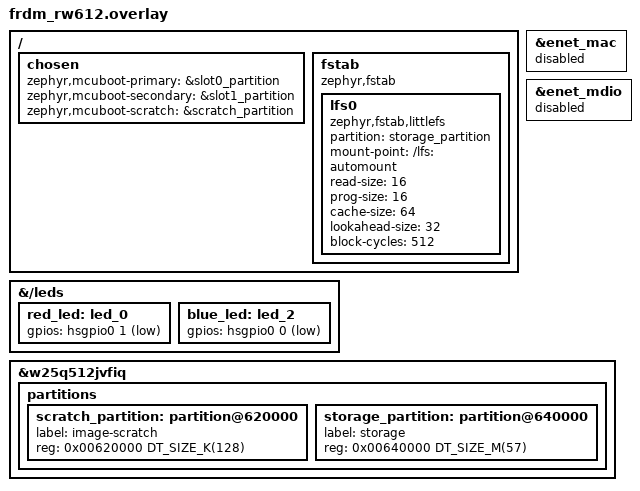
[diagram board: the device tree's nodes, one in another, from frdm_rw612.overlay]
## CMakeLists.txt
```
include(cmake/warn_all.cmake)

cmake_minimum_required(VERSION 3.20.0)

# Auto-include credentials.conf if present — keep it out of git
if(EXISTS ${CMAKE_CURRENT_SOURCE_DIR}/credentials.conf)
  list(APPEND EXTRA_CONF_FILE ${CMAKE_CURRENT_SOURCE_DIR}/credentials.conf)
endif()

find_package(Zephyr REQUIRED HINTS $ENV{ZEPHYR_BASE})
project(firmups_device LANGUAGES C)

warn_all(app)
target_include_directories(app PRIVATE include)
target_sources(app PRIVATE src/main.c src/application/common/fatal_error.c src/driver/common/filesystem.c)

if(${BOARD} MATCHES "native")
  zephyr_compile_options(-fsanitize-undefined-trap-on-error)
  target_sources(app PRIVATE
    src/udpclient.c
    src/application/native/firmware_updater.c
    src/driver/native/led.c
    src/driver/native/button.c)
  target_compile_definitions(app PUBLIC NATIVE_SIM)
elseif(${BOARD} MATCHES "nrf5340dk")
  target_sources(app PRIVATE
    src/application/nrf5340dk/firmware_updater.c
    src/driver/nrf5340dk/led.c
    src/driver/nrf5340dk/button.c)
  target_compile_definitions(app PUBLIC NRF5340DK)
elseif(${BOARD} MATCHES "frdm_rw612")
  if("${CONFIG_APP_WIFI_SSID}" STREQUAL "")
    message(FATAL_ERROR "CONFIG_APP_WIFI_SSID is empty. "
      "Create firmware/credentials.conf with:\n"
      "  CONFIG_APP_WIFI_SSID=\"<ssid>\"\n"
      "  CONFIG_APP_WIFI_PSK=\"<passphrase>\"\n"
      "(file is gitignored)")
  endif()
  if("${CONFIG_APP_WIFI_PSK}" STREQUAL "")
    message(FATAL_ERROR "CONFIG_APP_WIFI_PSK is empty. "
      "Create firmware/credentials.conf with:\n"
      "  CONFIG_APP_WIFI_SSID=\"<ssid>\"\n"
      "  CONFIG_APP_WIFI_PSK=\"<passphrase>\"\n"
      "(file is gitignored)")
  endif()
  target_sources(app PRIVATE
    src/udpclient.c
    src/application/frdm_rw612/firmware_updater.c
    src/application/frdm_rw612/wifi_connect.c
    src/driver/frdm_rw612/led.c
    src/driver/frdm_rw612/button.c)
  target_compile_definitions(app PUBLIC FRDM_RW612)
else()
  target_sources(app PRIVATE
    src/udpclient.c
    src/application/stm32h573i/firmware_updater.c
    src/driver/stm32h573i/led.c
    src/driver/stm32h573i/button.c)
endif()
```

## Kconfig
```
source "Kconfig.zephyr"

config APP_WIFI_SSID
	string "WiFi SSID"
	default ""
	help
	  SSID of the network to join. Set in credentials.conf (not tracked by git).

config APP_WIFI_PSK
	string "WiFi passphrase"
	default ""
	help
	  WPA2 passphrase. Set in credentials.conf (not tracked by git).
```

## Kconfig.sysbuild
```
source "share/sysbuild/Kconfig"

config NET_CORE_BOARD
	string
	default "nrf5340dk/nrf5340/cpunet" if $(BOARD) = "nrf5340dk"

config NET_CORE_IMAGE_HCI_IPC
	bool "HCI IPC image on network core"
	default y
	depends on NET_CORE_BOARD != ""
```

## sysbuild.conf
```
# Sysbuild configuration file.
SB_CONFIG_BOOTLOADER_MCUBOOT=y
#SB_CONFIG_MCUBOOT_MODE_OVERWRITE_ONLY=y
SB_CONFIG_MCUBOOT_MODE_SWAP_SCRATCH=y
```

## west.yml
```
manifest:
  remotes:
    - name: zephyrproject-rtos
      url-base: https://github.com/zephyrproject-rtos
    - name: firmups
      url-base: https://github.com/firmups
    - name: firmups-ssh
      url-base: git@github.com:firmups
    - name: mcuboot
      url-base: https://github.com/mcu-tools
  projects:
    - name: zephyr
      path: zephyr
      remote: zephyrproject-rtos
      revision: v4.4.0
      west-commands: scripts/west-commands.yml
      import:
        name-allowlist:
          - cmsis
          - cmsis_6
          - hal_nxp
          - hal_stm32
          - hal_nordic
          - segger
          - fatfs
          - littlefs
          - mcuboot
          - mbedtls
          - tf-psa-crypto
          - open-amp
          - libmetal
    - name: firmups-device-sdk
      repo-path: device-sdk
      path: ./modules/lib/firmups-device-sdk
      remote: firmups
      revision: gateway-functionality
      submodules: true
    - name: zephyr-bluethoot-integration
      path: ./modules/lib/zephyr-bluethoot-integration
      remote: firmups-ssh
      revision: main
```

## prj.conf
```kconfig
###############################################################################
# ZEPHYR CONFIGURATION
###############################################################################
# Generic drivers, libraries and frameworks
CONFIG_SMF=y
CONFIG_GPIO=y
CONFIG_HWINFO=y

# Logging
CONFIG_LOG=y
CONFIG_CBPRINTF_FP_SUPPORT=y
CONFIG_LOG_PROCESS_THREAD_SLEEP_MS=200
CONFIG_LOG_BUFFER_SIZE=4512

# Shell
CONFIG_SHELL=y
CONFIG_NET_SHELL=y

# Stacks
CONFIG_MAIN_STACK_SIZE=4512
CONFIG_ISR_STACK_SIZE=4512
CONFIG_SHELL_STACK_SIZE=4500
CONFIG_SYSTEM_WORKQUEUE_STACK_SIZE=2048

# Heaps
CONFIG_HEAP_MEM_POOL_SIZE=16000

# Real Time Clock (RTC)
CONFIG_RTC=y


# Assertion
CONFIG_ASSERT=y
CONFIG_ASSERT_LEVEL=2

# General networking
CONFIG_NETWORKING=y

# Networking
CONFIG_NET_CONFIG_SETTINGS=y
CONFIG_NET_CONFIG_NEED_IPV4=y

# Data link layer
CONFIG_NET_L2_ETHERNET=y

# Network layer
CONFIG_NET_IPV4=y
CONFIG_NET_CONTEXT_RECV_PKTINFO=y

# Transport layer
CONFIG_NET_SOCKETS=y
CONFIG_NET_UDP=y
CONFIG_NET_TCP=y
CONFIG_NET_TCP_KEEPALIVE=y

# Application layer
CONFIG_NET_HOSTNAME_ENABLE=y
CONFIG_NET_HOSTNAME="firmups-device"

###############################################################################
# MODULE CONFIGURATION
###############################################################################
# LED Button
# CONFIG_C_LED_BUTTON=y
# CONFIG_C_LED_BUTTON_LOG_LEVEL_DBG=y

# Disk access and filesystem
CONFIG_DISK_ACCESS=y
CONFIG_DISK_DRIVERS=y
CONFIG_FILE_SYSTEM=y

# Optional for file system shell
CONFIG_FILE_SYSTEM_SHELL=y

# Can be tinkered with to adjust network speed
CONFIG_NET_PKT_TX_COUNT=14
CONFIG_NET_BUF_TX_COUNT=50
CONFIG_REBOOT=y

CONFIG_SYSTEM_WORKQUEUE_STACK_SIZE=8192
```

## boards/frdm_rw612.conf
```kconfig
###############################################################################
# frdm_rw612 board config
###############################################################################

# LittleFS on external QSPI flash (no SD card on this board)
CONFIG_FILE_SYSTEM_LITTLEFS=y
CONFIG_FILE_SYSTEM_MKFS=y

# Flash drivers
CONFIG_FLASH=y
CONFIG_FLASH_MAP=y
CONFIG_FLASH_PAGE_LAYOUT=y

# MCUboot
CONFIG_IMG_MANAGER=y
CONFIG_MCUBOOT_IMG_MANAGER=y
CONFIG_STREAM_FLASH=y

# WiFi — NXP RW612 integrated radio
CONFIG_WIFI=y
CONFIG_WIFI_NXP=y
CONFIG_NXP_RW610=y
CONFIG_ETH_DRIVER=n
CONFIG_NET_L2_WIFI_MGMT=y
CONFIG_NET_CONFIG_AUTO_INIT=y

# DHCPv4 (overrides any static IP from prj.conf)
CONFIG_NET_DHCPV4=y
CONFIG_NET_CONFIG_INIT_TIMEOUT=30

# Stack sizes for WiFi
CONFIG_NET_MGMT_EVENT_STACK_SIZE=4608

CONFIG_NEWLIB_LIBC=y

CONFIG_LOG=y
CONFIG_NET_LOG=y
CONFIG_LOG_DEFAULT_LEVEL=3
CONFIG_FIRMUPS_LOG_LEVEL_INF=y
CONFIG_LOG_BUFFER_SIZE=8192

# Bluetooth — NXP RW612 integrated radio
CONFIG_BT=y
CONFIG_BT_PERIPHERAL=y
CONFIG_BT_DEVICE_NAME="firmups-device"

# ATT MTU — match nRF5340 central; allows 514-byte firmware chunks per notification
CONFIG_BT_L2CAP_TX_MTU=517
CONFIG_BT_BUF_ACL_TX_SIZE=521
CONFIG_BT_BUF_ACL_RX_SIZE=521

# Firmups BT Gateway
CONFIG_FIRMUPS_GATEWAY=y
CONFIG_FIRMUPS_BT_GATEWAY=y
CONFIG_FIRMUPS_BT_GATEWAY_RESPONSE_BUFFER_SIZE=514

CONFIG_BT_MAX_CONN=4
```

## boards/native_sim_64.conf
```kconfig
CONFIG_NEWLIB_LIBC=y
CONFIG_UBSAN=y
CONFIG_ASAN=y
CONFIG_ETH_NATIVE_TAP=y
CONFIG_NET_CONFIG_AUTO_INIT=y

# Filesystem core
CONFIG_FILE_SYSTEM_LITTLEFS=y
CONFIG_FILE_SYSTEM_MKFS=y

# Flash map & partition support
CONFIG_FLASH=y
CONFIG_FLASH_MAP=y
CONFIG_FLASH_PAGE_LAYOUT=y

# Optional logging
CONFIG_LOG=y
```

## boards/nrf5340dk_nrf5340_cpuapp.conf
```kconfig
###############################################################################
# nrf5340dk_nrf5340_cpuapp board config
###############################################################################

# Flash drivers
CONFIG_FLASH=y
CONFIG_FLASH_MAP=y
CONFIG_FLASH_PAGE_LAYOUT=y

# MCUboot
CONFIG_IMG_MANAGER=y
CONFIG_MCUBOOT_IMG_MANAGER=y
CONFIG_STREAM_FLASH=y

# Bluetooth — central role towards RW612 gateway
CONFIG_BT=y
CONFIG_BT_CENTRAL=y
CONFIG_BT_GATT_CLIENT=y
CONFIG_BT_DEVICE_NAME="firmups-nrf5340"

# ATT MTU — 517 bytes allows 514-byte firmware chunk notifications from RW612
CONFIG_BT_L2CAP_TX_MTU=517
CONFIG_BT_BUF_ACL_TX_SIZE=521
CONFIG_BT_BUF_ACL_RX_SIZE=521

# Disable UICR-based APPROTECT so the firmware doesn't re-lock the chip
# after flashing (factory UICR has APPROTECT=0x00 which means "locked")
CONFIG_NRF_APPROTECT_USE_UICR=n
CONFIG_NRF_SECURE_APPROTECT_USE_UICR=n

CONFIG_LOG=y
CONFIG_LOG_DEFAULT_LEVEL=3
CONFIG_FIRMUPS_LOG_LEVEL_INF=y
CONFIG_LOG_BUFFER_SIZE=8192
```

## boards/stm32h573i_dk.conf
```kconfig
###############################################################################
# stm32h573i_dk board overlay
###############################################################################

# Static IP configuration
CONFIG_NET_CONFIG_MY_IPV4_ADDR="192.0.2.1"
CONFIG_NET_CONFIG_PEER_IPV4_ADDR="192.0.2.2"
CONFIG_NET_CONFIG_MY_IPV4_NETMASK="255.255.255.0"
CONFIG_NET_CONFIG_MY_IPV4_GW="192.0.0.254"
CONFIG_NET_CONFIG_INIT_TIMEOUT=5
CONFIG_TEST_RANDOM_GENERATOR=y
CONFIG_TIMER_RANDOM_GENERATOR=y
CONFIG_NEWLIB_LIBC=y

## Fatfs for SD-Card
CONFIG_DISK_DRIVER_SDMMC=y
CONFIG_FS_FATFS_NUM_FILES=6
CONFIG_FS_FATFS_LFN=y
# CONFIG_FS_FATFS_REENTRANT=y
# CONFIG_FS_FATFS_CUSTOM_MOUNT_POINT_COUNT=1
# CONFIG_FS_FATFS_CUSTOM_MOUNT_POINTS="data"

CONFIG_FILE_SYSTEM=y
CONFIG_FILE_SYSTEM_MKFS=y
CONFIG_FAT_FILESYSTEM_ELM=y
CONFIG_FS_FATFS_FSTAB_AUTOMOUNT=y

# MCUboot
CONFIG_IMG_MANAGER=y
CONFIG_MCUBOOT_IMG_MANAGER=y
CONFIG_STREAM_FLASH=y
CONFIG_FLASH=y
CONFIG_FLASH_MAP=y
CONFIG_FLASH_PAGE_LAYOUT=y
```

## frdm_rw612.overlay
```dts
/* FRDM-RW612 overlay
 *
 * - Disables Ethernet MAC/MDIO (using integrated WiFi instead)
 * - Sets MCUboot chosen partition references
 * - Carves a 128 KB scratch partition out of the flash area that the board DTS
 *   assigns entirely to storage, then remaps storage to start after scratch
 * - Mounts LittleFS on the storage partition (no SD card on this board)
 */

/* Disable Ethernet — using integrated WiFi radio instead */
&enet_mac {
	status = "disabled";
};

&enet_mdio {
	status = "disabled";
};

/delete-node/ &storage_partition;

/* Add red and blue to the RGB LED (green is defined in board DTS on hsgpio0 pin 12) */
&{/leds} {
	red_led: led_0 {
		gpios = <&hsgpio0 1 GPIO_ACTIVE_LOW>;
	};
	blue_led: led_2 {
		gpios = <&hsgpio0 0 GPIO_ACTIVE_LOW>;
	};
};

/ {
	chosen {
		zephyr,mcuboot-primary   = &slot0_partition;
		zephyr,mcuboot-secondary = &slot1_partition;
		zephyr,mcuboot-scratch   = &scratch_partition;
	};

	fstab {
		compatible = "zephyr,fstab";

		lfs0: lfs0 {
			compatible = "zephyr,fstab,littlefs";
			partition = <&storage_partition>;
			mount-point = "/lfs:";
			automount;
			read-size = <16>;
			prog-size = <16>;
			cache-size = <64>;
			lookahead-size = <32>;
			block-cycles = <512>;
		};
	};
};

/* The board DTS places storage_partition at 0x620000.
 * We insert a 128 KB scratch partition there, then push storage to 0x640000.
 */
&w25q512jvfiq {
	partitions {
		scratch_partition: partition@620000 {
			label = "image-scratch";
			reg = <0x00620000 DT_SIZE_K(128)>;
		};

		storage_partition: partition@640000 {
			label = "storage";
			reg = <0x00640000 DT_SIZE_M(57)>;
		};
	};
};
```

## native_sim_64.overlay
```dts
/* Nativesim-specific overlay to the standard DeviceTree
 *
 * Enables littlefs on storage partition
 */

/ {
    fstab {
        compatible = "zephyr,fstab";

        lfs0: lfs0 {
            compatible = "zephyr,fstab,littlefs";
            partition = <&storage_partition>;  // bind to your fixed partition
            mount-point = "/lfs:";
            automount;
            // Optional flags:
            // readonly;                      // if you need RO mount
            read-size = <16>;
            prog-size = <16>;
            cache-size = <64>;
            lookahead-size = <32>;
            block-cycles = <512>;
        };
    };

    sram123: memory@20000000 {
        compatible = "mmio-sram";
        reg = <0x20000000 DT_SIZE_K(640)>;
    };
};

&storage_partition {
    reg = <0x000fc000 0x00080000>; // 512 KiB could be up to 1MiB
    label = "storage";
};
```

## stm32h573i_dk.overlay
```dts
/* STM32H573-specific overlay to the standard DeviceTree
 *
 * SRAM1, SRAM2 and SRAM3 are contiguous so they are clustered
 * together to take advantage of the space they have to offer.
 */

/delete-node/ &sram1;
/delete-node/ &sram2;
/delete-node/ &sram3;

/ {
    chosen {
        zephyr,sram = &sram123;
        zephyr,mcuboot-primary = &slot0_partition;
        zephyr,mcuboot-secondary = &slot1_partition;
        zephyr,mcuboot-scratch = &scratch_partition;
    };

    fstab {
        compatible = "zephyr,fstab";
        data1: data1 {
            compatible = "zephyr,fstab,fatfs";
            automount;
            disk-access;
			mount-point = "/SD:";
        };
    };

    sram123: memory@20000000 {
        compatible = "mmio-sram";
        reg = <0x20000000 DT_SIZE_K(640)>;
    };
};

&flash0 {
    partitions {
        compatible = "fixed-partitions";
        #address-cells = <1>;
        #size-cells = <1>;

        /delete-node/ partition@0;
        /delete-node/ partition@10000;
        /delete-node/ partition@80000;
        /delete-node/ partition@ee000;

        boot_partition: partition@0 {
            label = "mcuboot";
            reg = <0x00000000 DT_SIZE_K(64)>;
        };

        slot0_partition: partition@10000 {
            label = "image-0";
            reg = <0x00010000 DT_SIZE_K(768)>;  // spans Bank1
        };

        slot1_partition: partition@D0000 {
            label = "image-1";
            reg = <0x000D0000 DT_SIZE_K(768)>;  // starts in Bank2
        };

        scratch_partition: partition@190000 {
            label = "image-scratch";
            reg = <0x00190000 DT_SIZE_K(64)>;
            };

        storage_partition: partition@1A0000 {
            label = "storage";
            reg = <0x001A0000 DT_SIZE_K(64)>;
        };
    };
};

&sdmmc1 {
    clk-div = <3>;
};
```

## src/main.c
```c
/*
 * Copyright (c) 2012-2014 Wind River Systems, Inc.
 *
 * SPDX-License-Identifier: Apache-2.0
 */
#include <firmups-device-sdk/sdk.h>
#include <stdio.h>
#include <zephyr/kernel.h>
#include <zephyr/logging/log.h>

#include "button.h"
#include "led.h"
#include "firmware_updater.h"
#include "fatal_error.h"

LOG_MODULE_REGISTER(main, CONFIG_FIRMUPS_LOG_LEVEL);
static const uint32_t firmware_version = 1;
static struct firmware_updater_context *fw_u_c;

static void firmware_check(void)
{
#ifdef NRF5340DK
	if (!firmware_updater_connect(fw_u_c)) {
		return;
	}
#endif
	if (firmware_update_available(fw_u_c)) {
		int ret = firmware_updater_update_firmware(fw_u_c);
		if (ret < 0) {
			LOG_ERR("Firmware update failed");
		}
	} else {
		LOG_INF("No firmware update required");
	}
#ifdef NRF5340DK
	firmware_updater_disconnect(fw_u_c);
#endif
}

int main(void)
{
	uint32_t device_id = 1; // Example device ID
	uint8_t sdk_work_buffer[2048];

	led_initialize();
	led_blink_start(LED_BLUE);
	fw_u_c = firmware_updater_initialize(sdk_work_buffer, sizeof(sdk_work_buffer), device_id,
					     firmware_version);
	if (fw_u_c == NULL) {
		LOG_ERR("Firmware updater context could not be initialized");
		blink_red_led_forever();
	}
	button_init(firmware_check);

	while (true) {
		k_sleep(K_MSEC(100000));
	}
}
```

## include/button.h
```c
#ifndef BUTTON_H
#define BUTTON_H

void button_init(void (*callback)(void));

#endif // BUTTON_H
```

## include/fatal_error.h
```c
#ifndef FATAL_ERROR_H
#define FATAL_ERROR_H

void blink_red_led_forever(void);

#endif // FATAL_ERROR_H
```

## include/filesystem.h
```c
#ifndef FILESYSTEM_H
#define FILESYSTEM_H

#include <stdint.h>
#include <stddef.h>

#if defined(NATIVE_SIM) || defined(FRDM_RW612)
#define FILESYSTEM_MOUNT_POINT "/lfs:"
#else
#define FILESYSTEM_MOUNT_POINT "/SD:"
#endif

char const *filesystem_get_mount_point(void);
int filesystem_append_bytes(const char *path, const uint8_t *data, size_t len);

#endif // FILESYSTEM_H
```

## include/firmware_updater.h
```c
#ifndef FIRMWARE_UPDATER_H
#define FIRMWARE_UPDATER_H

#include <stdint.h>
#include <stdbool.h>

struct firmware_updater_context;

struct firmware_updater_context *firmware_updater_initialize(uint8_t *work_buffer,
							     uint32_t work_buffer_size,
							     uint32_t device_id,
							     uint32_t firmware_version);
bool firmware_update_available(struct firmware_updater_context *context);
uint32_t firmware_updater_get_firmware_version(struct firmware_updater_context *context);
int firmware_updater_update_firmware(struct firmware_updater_context *context);

#ifdef NRF5340DK
bool firmware_updater_connect(struct firmware_updater_context *context);
void firmware_updater_disconnect(struct firmware_updater_context *context);
#endif

#endif // FIRMWARE_UPDATER_H
```

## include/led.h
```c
#ifndef LED_H
#define LED_H

enum led_type {
	LED_GREEN,
	LED_ORANGE,
	LED_RED,
	LED_BLUE,
	LED_END,
};

int led_initialize(void);
void led_blink_start(enum led_type led);
void led_blink_end(enum led_type led);

#endif // LED_H
```

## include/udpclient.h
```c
#ifndef UDPCLIENT_H
#define UDPCLIENT_H

#include <stdint.h>
#include <firmups-device-sdk/error.h>

enum firmups_sdk_error_code udp_send_data(uint8_t *send_buffer, uint16_t send_buffer_size,
					  uint8_t *response_buffer, uint16_t response_buffer_size,
					  uint16_t *response_size, void *userdata);

#endif // UDPCLIENT_H
```

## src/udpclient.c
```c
#include <zephyr/net/socket.h>
#include <zephyr/kernel.h>
#include <string.h>
#include <stdio.h>
#include <zephyr/net/net_ip.h>
#include "udpclient.h"
#include <zephyr/logging/log.h>

LOG_MODULE_REGISTER(udp_client);

#define SERVER_ADDR "192.0.2.2" // Replace with your server IP
#define SERVER_PORT 53585

static int recv_with_timeout(int sock, void *buf, size_t len, int timeout_ms)
{
	struct zsock_pollfd pfd = {
		.fd = sock,
		.events = ZSOCK_POLLIN,
		.revents = 0,
	};

	int pr = zsock_poll(&pfd, 1, timeout_ms);
	if (pr == 0) {
		LOG_INF("Socket receive timeout");
		errno = EAGAIN; // timeout
		return -1;
	}
	if (pr < 0) {
		// errno set by poll
		return -1;
	}

	// Ready for read
	return zsock_recv(sock, buf, len, 0);
}

enum firmups_sdk_error_code udp_send_data(uint8_t *send_buffer, uint16_t send_buffer_size,
					  uint8_t *response_buffer, uint16_t response_buffer_size,
					  uint16_t *response_size, void *userdata)
{
	int sock;
	struct sockaddr_in server_addr;
	(void)userdata; // Unused parameter

	// Create UDP socket
	sock = zsock_socket(AF_INET, SOCK_DGRAM, IPPROTO_UDP);
	if (sock < 0) {
		LOG_ERR("Failed to create socket\n");
		return FIRMUPS_SDK_ERROR_COMMUNICATION_FAILURE;
	}

	// Set up server address
	server_addr.sin_family = AF_INET;
	server_addr.sin_port = htons(SERVER_PORT);

	int ret = net_addr_pton(AF_INET, SERVER_ADDR, &server_addr.sin_addr);
	if (ret < 0) {
		LOG_ERR("Invalid IP address\n");
		zsock_close(sock);
		return -1;
	}

	// Send message to server
	int sent = zsock_sendto(sock, send_buffer, send_buffer_size, 0,
				(struct sockaddr *)&server_addr, sizeof(server_addr));
	if (sent < 0) {
		LOG_ERR("Failed to send data\n");
		zsock_close(sock);
		return FIRMUPS_SDK_ERROR_COMMUNICATION_FAILURE;
	}

	LOG_DBG("Sent %d bytes to server\n", sent);

	// Receive response
	int received = recv_with_timeout(sock, response_buffer, response_buffer_size, 5000);
	// int received = zsock_recv(sock, response_buffer, response_buffer_size, 0);
	if (received > 0) {
		LOG_DBG("Received %d bytes\n", received);
		*response_size = received;
	} else {
		LOG_ERR("No response or error receiving\n");
		zsock_close(sock);
		return FIRMUPS_SDK_ERROR_TIMEOUT;
	}

	zsock_close(sock);
	return FIRMUPS_SDK_ERROR_NONE;
}
```
